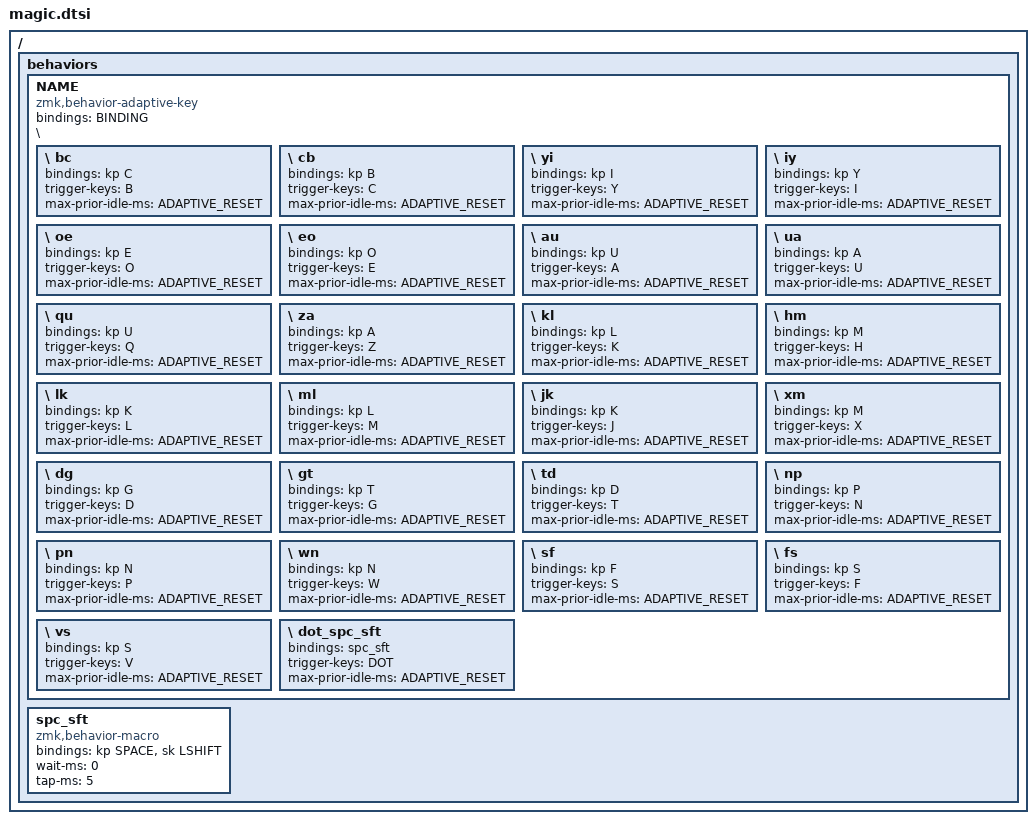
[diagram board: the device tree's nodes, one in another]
#define ADAPTIVE_RESET 1200
#define MAGIC_KEY(NAME, BINDING) \
    ZMK_ADAPTIVE_KEY(NAME, bindings = <BINDING>; \
        // Alpha SFBs \
        bc {bindings = <&kp C>; trigger-keys = <B>; max-prior-idle-ms = <ADAPTIVE_RESET>;}; \
        cb {bindings = <&kp B>; trigger-keys = <C>; max-prior-idle-ms = <ADAPTIVE_RESET>;}; \
        yi {bindings = <&kp I>; trigger-keys = <Y>; max-prior-idle-ms = <ADAPTIVE_RESET>;}; \
        iy {bindings = <&kp Y>; trigger-keys = <I>; max-prior-idle-ms = <ADAPTIVE_RESET>;}; \
        oe {bindings = <&kp E>; trigger-keys = <O>; max-prior-idle-ms = <ADAPTIVE_RESET>;}; \
        eo {bindings = <&kp O>; trigger-keys = <E>; max-prior-idle-ms = <ADAPTIVE_RESET>;}; \
        au {bindings = <&kp U>; trigger-keys = <A>; max-prior-idle-ms = <ADAPTIVE_RESET>;}; \
        ua {bindings = <&kp A>; trigger-keys = <U>; max-prior-idle-ms = <ADAPTIVE_RESET>;}; \
        qu {bindings = <&kp U>; trigger-keys = <Q>; max-prior-idle-ms = <ADAPTIVE_RESET>;}; \
        za {bindings = <&kp A>; trigger-keys = <Z>; max-prior-idle-ms = <ADAPTIVE_RESET>;}; \
        kl {bindings = <&kp L>; trigger-keys = <K>; max-prior-idle-ms = <ADAPTIVE_RESET>;}; \
        hm {bindings = <&kp M>; trigger-keys = <H>; max-prior-idle-ms = <ADAPTIVE_RESET>;}; \
        lk {bindings = <&kp K>; trigger-keys = <L>; max-prior-idle-ms = <ADAPTIVE_RESET>;}; \
        ml {bindings = <&kp L>; trigger-keys = <M>; max-prior-idle-ms = <ADAPTIVE_RESET>;}; \
        jk {bindings = <&kp K>; trigger-keys = <J>; max-prior-idle-ms = <ADAPTIVE_RESET>;}; \
        xm {bindings = <&kp M>; trigger-keys = <X>; max-prior-idle-ms = <ADAPTIVE_RESET>;}; \
        dg {bindings = <&kp G>; trigger-keys = <D>; max-prior-idle-ms = <ADAPTIVE_RESET>;}; \
        gt {bindings = <&kp T>; trigger-keys = <G>; max-prior-idle-ms = <ADAPTIVE_RESET>;}; \
        td {bindings = <&kp D>; trigger-keys = <T>; max-prior-idle-ms = <ADAPTIVE_RESET>;}; \
        np {bindings = <&kp P>; trigger-keys = <N>; max-prior-idle-ms = <ADAPTIVE_RESET>;}; \
        pn {bindings = <&kp N>; trigger-keys = <P>; max-prior-idle-ms = <ADAPTIVE_RESET>;}; \
        wn {bindings = <&kp N>; trigger-keys = <W>; max-prior-idle-ms = <ADAPTIVE_RESET>;}; \
        sf {bindings = <&kp F>; trigger-keys = <S>; max-prior-idle-ms = <ADAPTIVE_RESET>;}; \
        fs {bindings = <&kp S>; trigger-keys = <F>; max-prior-idle-ms = <ADAPTIVE_RESET>;}; \
        vs {bindings = <&kp S>; trigger-keys = <V>; max-prior-idle-ms = <ADAPTIVE_RESET>;}; \
        dot_spc_sft {bindings = <&spc_sft>; trigger-keys = <DOT>; max-prior-idle-ms = <ADAPTIVE_RESET>;}; \
    )
    
ZMK_MACRO(spc_sft, bindings = <&kp SPACE &sk LSHIFT>; wait-ms = <0>; tap-ms = <5>;)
